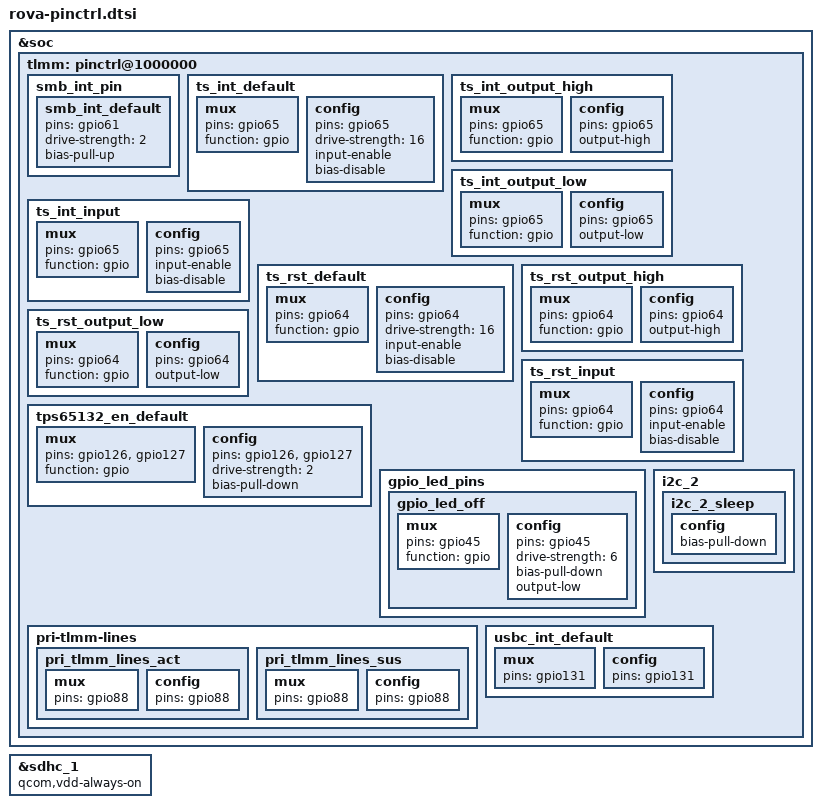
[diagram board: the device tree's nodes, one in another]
/*
 * Copyright (c) 2015-2017, The Linux Foundation. All rights reserved.
 * Copyright (C) 2018 XiaoMi, Inc.
 *
 * This program is free software; you can redistribute it and/or modify
 * it under the terms of the GNU General Public License version 2 and
 * only version 2 as published by the Free Software Foundation.
 *
 * This program is distributed in the hope that it will be useful,
 * but WITHOUT ANY WARRANTY; without even the implied warranty of
 * MERCHANTABILITY or FITNESS FOR A PARTICULAR PURPOSE.  See the
 * GNU General Public License for more details.
 */

&soc {
	tlmm: pinctrl@1000000 {
		smb_int_pin {
			smb_int_default: smb_int_default {
				pins = "gpio61";
				drive-strength = <2>;	/*8 MA */
				bias-pull-up;		/* PULL UP*/
			};
		};

		/* add pingrp for goodix touch */
		ts_int_default: ts_int_default {
			mux {
				pins = "gpio65";
				function = "gpio";
			};
			config {
				pins = "gpio65";
				drive-strength = <16>;
				/*bias-pull-up;*/
				input-enable;
				bias-disable;
			};
		};

		ts_int_output_high: ts_int_output_high {
			mux {
				pins = "gpio65";
				function = "gpio";
			};
			config {
				pins = "gpio65";
				output-high;
			};
		};

		ts_int_output_low: ts_int_output_low {
			mux {
				pins = "gpio65";
				function = "gpio";
			};
			config {
				pins = "gpio65";
				output-low;
			};
		};

		ts_int_input: ts_int_input {
			mux {
				pins = "gpio65";
				function = "gpio";
			};
			config {
				pins = "gpio65";
				input-enable;
				bias-disable;
			};
		};

		ts_rst_default: ts_rst_default {
			mux {
				pins = "gpio64";
				function = "gpio";
			};
			config {
				pins = "gpio64";
				drive-strength = <16>;
				/*bias-pull-up;*/
				input-enable;
				bias-disable;
			};
		};

		ts_rst_output_high: ts_rst_output_high {
			mux {
				pins = "gpio64";
				function = "gpio";
			};
			config {
				pins = "gpio64";
				output-high;
			};
		};

		ts_rst_output_low: ts_rst_output_low {
			mux {
				pins = "gpio64";
				function = "gpio";
			};
			config {
				pins = "gpio64";
				output-low;
			};
		};

		ts_rst_input: ts_rst_input {
			mux {
				pins = "gpio64";
				function = "gpio";
			};
			config {
				pins = "gpio64";
				input-enable;
				bias-disable;
			};
		};

		tps65132_en_default: tps65132_en_default {
			mux {
				pins = "gpio126", "gpio127";
				function = "gpio";
			};
			config {
				pins = "gpio126", "gpio127";
				drive-strength = <2>;
				bias-pull-down;
			};
		};
 		
		gpio_led_pins {
			gpio_led_off: gpio_led_off {
				mux {
					pins = "gpio45";
					function = "gpio";
			        };
				config {
					pins = "gpio45";
					drive-strength = <6>;
					bias-pull-down;
					output-low;
				};
			};
		};

		pri-tlmm-lines {
			pri_tlmm_lines_act: pri_tlmm_lines_act {
				mux {
					pins = "gpio88";
				};

				config {
					pins = "gpio88";
				};
			};

			pri_tlmm_lines_sus: pri_tlmm_lines_sus {
				mux {
					pins = "gpio88";
				};

				config {
					pins = "gpio88";
				};
			};
		};

		i2c_2 {
			i2c_2_sleep: i2c_2_sleep {
				config {
					/delete-property/ bias-disable;
					bias-pull-down;
				};
			};
		};

		usbc_int_default: usbc_int_default {
			mux {
				pins = "gpio131";
			};

			config {
				pins = "gpio131";
			};
		};
	};
};

&sdhc_1 {
	qcom,vdd-always-on;
};
